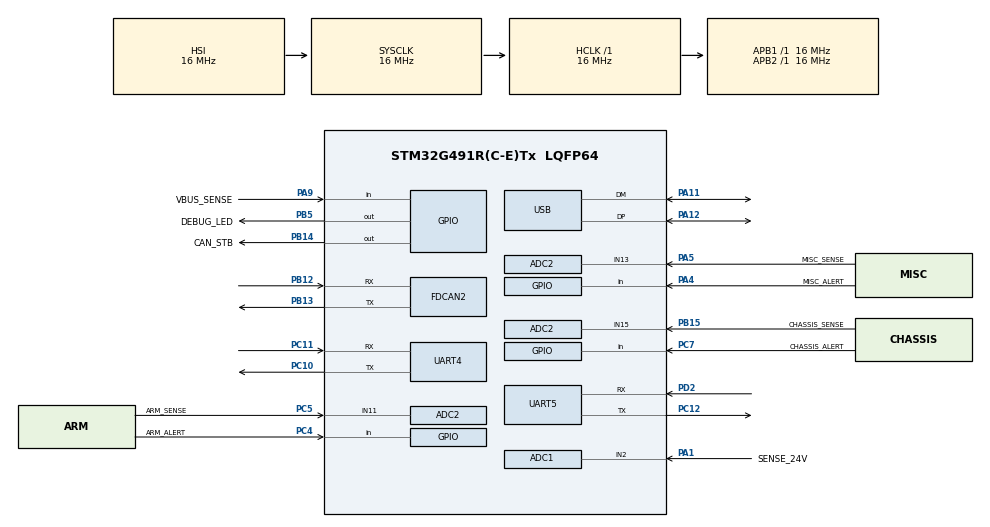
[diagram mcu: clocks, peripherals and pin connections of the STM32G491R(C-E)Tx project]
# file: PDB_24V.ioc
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ADC1.Channel-2\#ChannelRegularConversion=ADC_CHANNEL_2
ADC1.NbrOfConversion=1
ADC1.NbrOfConversionFlag=1
ADC1.OffsetNumber-2\#ChannelRegularConversion=ADC_OFFSET_NONE
ADC1.OversamplingMode=ENABLE
ADC1.Rank-2\#ChannelRegularConversion=1
ADC1.Ratio=ADC_OVERSAMPLING_RATIO_64
ADC1.RightBitShift=ADC_RIGHTBITSHIFT_2
ADC1.SamplingTime-2\#ChannelRegularConversion=ADC_SAMPLETIME_2CYCLES_5
ADC1.master=1
ADC2.Channel-0\#ChannelRegularConversion=ADC_CHANNEL_13
ADC2.NbrOfConversionFlag=1
ADC2.OffsetNumber-0\#ChannelRegularConversion=ADC_OFFSET_NONE
ADC2.OversamplingMode=ENABLE
ADC2.Rank-0\#ChannelRegularConversion=1
ADC2.Ratio=ADC_OVERSAMPLING_RATIO_64
ADC2.RightBitShift=ADC_RIGHTBITSHIFT_2
ADC2.SamplingTime-0\#ChannelRegularConversion=ADC_SAMPLETIME_2CYCLES_5
ADC3.Channel-0\#ChannelRegularConversion=ADC_CHANNEL_VREFINT
ADC3.NbrOfConversionFlag=1
ADC3.OffsetNumber-0\#ChannelRegularConversion=ADC_OFFSET_NONE
ADC3.Rank-0\#ChannelRegularConversion=1
ADC3.SamplingTime-0\#ChannelRegularConversion=ADC_SAMPLETIME_2CYCLES_5
ADC3.master=1
FDCAN2.CalculateBaudRateNominal=333333
FDCAN2.CalculateTimeBitNominal=3000
FDCAN2.CalculateTimeQuantumNominal=1000.0
Mcu.Family=STM32G4
Mcu.Name=STM32G491R(C-E)Tx
Mcu.Package=LQFP64
NVIC.PriorityGroup=NVIC_PRIORITYGROUP_4
NVIC.UART4_IRQn=true\:0\:0\:false\:false\:true\:true\:true\:true
PA1.GPIO_Label=SENSE_24V
PA1.Mode=IN2-Single-Ended
PA1.Signal=ADC1_IN2
PA11.Mode=Device
PA11.Signal=USB_DM
PA12.Mode=Device
PA12.Signal=USB_DP
PA13.Mode=Serial_Wire
PA13.Signal=SYS_JTMS-SWDIO
PA14.Mode=Serial_Wire
PA14.Signal=SYS_JTCK-SWCLK
PA4.GPIO_Label=MISC_ALERT
PA4.Signal=GPIO_Input
PA5.GPIO_Label=MISC_SENSE
PA5.Mode=IN13-Single-Ended
PA5.Signal=ADC2_IN13
PA9.GPIO_Label=VBUS_SENSE
PA9.Signal=GPIO_Input
PB12.Mode=FDCAN_Activate
PB12.Signal=FDCAN2_RX
PB13.Mode=FDCAN_Activate
PB13.Signal=FDCAN2_TX
PB14.GPIO_Label=CAN_STB
PB14.Signal=GPIO_Output
PB15.GPIO_Label=CHASSIS_SENSE
PB15.Mode=IN15-Single-Ended
PB15.Signal=ADC2_IN15
PB5.GPIO_Label=DEBUG_LED
PB5.Signal=GPIO_Output
PC10.Mode=Asynchronous
PC10.Signal=UART4_TX
PC11.Mode=Asynchronous
PC11.Signal=UART4_RX
PC12.Mode=Asynchronous
PC12.Signal=UART5_TX
PC14-OSC32_IN.Mode=LSE-External-Oscillator
PC14-OSC32_IN.Signal=RCC_OSC32_IN
PC15-OSC32_OUT.Mode=LSE-External-Oscillator
PC15-OSC32_OUT.Signal=RCC_OSC32_OUT
PC4.GPIO_Label=ARM_ALERT
PC4.Signal=GPIO_Input
PC5.GPIO_Label=ARM_SENSE
PC5.Mode=IN11-Single-Ended
PC5.Signal=ADC2_IN11
PC7.GPIO_Label=CHASSIS_ALERT
PC7.Signal=GPIO_Input
PD2.Mode=Asynchronous
PD2.Signal=UART5_RX
PF0-OSC_IN.Mode=HSE-External-Oscillator
PF0-OSC_IN.Signal=RCC_OSC_IN
PF1-OSC_OUT.Mode=HSE-External-Oscillator
PF1-OSC_OUT.Signal=RCC_OSC_OUT
ProjectManager.HeapSize=0x200
ProjectManager.StackSize=0x400
ProjectManager.TargetToolchain=CMake
RCC.AHBFreq_Value=16000000
RCC.APB1Freq_Value=16000000
RCC.APB1TimFreq_Value=16000000
RCC.APB2Freq_Value=16000000
RCC.APB2TimFreq_Value=16000000
RCC.CortexFreq_Value=16000000
RCC.EXTERNAL_CLOCK_VALUE=12288000
RCC.HCLKFreq_Value=16000000
RCC.HSE_VALUE=8000000
RCC.HSI48_VALUE=48000000
RCC.HSI_VALUE=16000000
RCC.SYSCLKFreq_VALUE=16000000
RCC.VCOOutputFreq_Value=128000000
VP_ADC3_Vref_Input.Mode=IN-Vrefint
VP_SYS_VS_DBSignals.Mode=DisableDeadBatterySignals
board=custom

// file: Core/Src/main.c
/* USER CODE BEGIN Header */
/**
  ******************************************************************************
  * @file           : main.c
  * @brief          : Main program body
  ******************************************************************************
  * @attention
  *
  * Copyright (c) 2026 STMicroelectronics.
  * All rights reserved.
  *
  * This software is licensed under terms that can be found in the LICENSE file
  * in the root directory of this software component.
  * If no LICENSE file comes with this software, it is provided AS-IS.
  *
  ******************************************************************************
  */
/* USER CODE END Header */
#include "main.h"
#include "adc.h"
#include "fdcan.h"
#include "stm32g4xx_hal_adc_ex.h"
#include "stm32g4xx_hal_gpio.h"
#include "usart.h"
#include "usb.h"
#include "gpio.h"

void SystemClock_Config(void);
/* USER CODE BEGIN PFP */
void app_main();
/* USER CODE END PFP */

int main(void)
{

  /* MCU Configuration--------------------------------------------------------*/

  /* Reset of all peripherals, Initializes the Flash interface and the Systick. */
  HAL_Init();

  /* Configure the system clock */
  SystemClock_Config();

  /* Initialize all configured peripherals */
  MX_GPIO_Init();
  MX_FDCAN2_Init();
  MX_UART4_Init();
  MX_UART5_Init();
  MX_USB_PCD_Init();
  MX_ADC1_Init();
  MX_ADC2_Init();
  MX_ADC3_Init();
  /* USER CODE BEGIN 2 */
  HAL_ADCEx_Calibration_Start(&hadc1, ADC_SINGLE_ENDED);
  HAL_ADCEx_Calibration_Start(&hadc2, ADC_SINGLE_ENDED);
  HAL_ADCEx_Calibration_Start(&hadc3, ADC_SINGLE_ENDED);

  app_main();
  /* USER CODE END 2 */

  /* Infinite loop */
  while (1)
  {
    /* USER CODE BEGIN 3 */
    HAL_GPIO_WritePin(DEBUG_LED_GPIO_Port, DEBUG_LED_Pin, GPIO_PIN_SET);

  }
  /* USER CODE END 3 */
}

void SystemClock_Config(void)
{
  RCC_OscInitTypeDef RCC_OscInitStruct = {0};
  RCC_ClkInitTypeDef RCC_ClkInitStruct = {0};

  /** Configure the main internal regulator output voltage
  */
  HAL_PWREx_ControlVoltageScaling(PWR_REGULATOR_VOLTAGE_SCALE1);

  /** Initializes the RCC Oscillators according to the specified parameters
  * in the RCC_OscInitTypeDef structure.
  */
  RCC_OscInitStruct.OscillatorType = RCC_OSCILLATORTYPE_HSI|RCC_OSCILLATORTYPE_HSI48;
  RCC_OscInitStruct.HSIState = RCC_HSI_ON;
  RCC_OscInitStruct.HSICalibrationValue = RCC_HSICALIBRATION_DEFAULT;
  RCC_OscInitStruct.HSI48State = RCC_HSI48_ON;
  RCC_OscInitStruct.PLL.PLLState = RCC_PLL_NONE;
  if (HAL_RCC_OscConfig(&RCC_OscInitStruct) != HAL_OK)
  {
    Error_Handler();
  }

  /** Initializes the CPU, AHB and APB buses clocks
  */
  RCC_ClkInitStruct.ClockType = RCC_CLOCKTYPE_HCLK|RCC_CLOCKTYPE_SYSCLK
                              |RCC_CLOCKTYPE_PCLK1|RCC_CLOCKTYPE_PCLK2;
  RCC_ClkInitStruct.SYSCLKSource = RCC_SYSCLKSOURCE_HSI;
  RCC_ClkInitStruct.AHBCLKDivider = RCC_SYSCLK_DIV1;
  RCC_ClkInitStruct.APB1CLKDivider = RCC_HCLK_DIV1;
  RCC_ClkInitStruct.APB2CLKDivider = RCC_HCLK_DIV1;

  if (HAL_RCC_ClockConfig(&RCC_ClkInitStruct, FLASH_LATENCY_0) != HAL_OK)
  {
    Error_Handler();
  }
}

void Error_Handler(void)
{
  __disable_irq();
  while (1)
  {
  }
}
